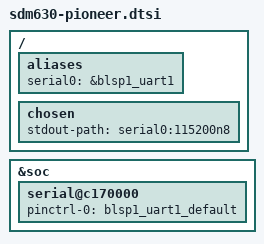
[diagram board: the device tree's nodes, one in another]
// SPDX-License-Identifier: GPL-2.0
/* Copyright (c) 2018, Craig Tatlor. */

#include "sdm630.dtsi"

/ {
	aliases {
		serial0 = &blsp1_uart1;
	};

	chosen {
		stdout-path = "serial0:115200n8";
	};
};

&soc {
	serial@c170000 {
		status = "okay";
		pinctrl-names = "default";
		pinctrl-0 = <&blsp1_uart1_default>;
	};
};
